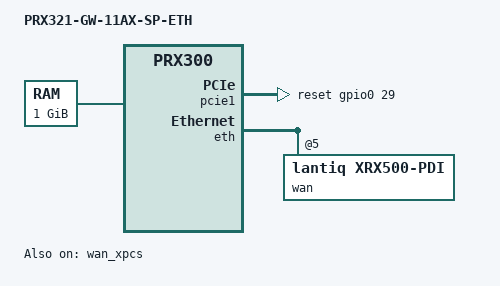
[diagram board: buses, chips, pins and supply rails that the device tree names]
/dts-v1/;
#include "prx321-gw-11ax-sp.dtsi"

/* Model configuration */
/ {
	model = "PRX321-GW-11AX-SP-ETH";
	compatible = "intel,prx321-gw-11ax-sp-eth", "intel,prx300";

	chosen {
		stdout-path = "serial0";
	};

	memory@0 {
		device_type = "memory";
		reg = <0x20000000 0x40000000>; /* 1024 MB */
	};
};

/* invert the reset polarity for VRX618 */
&pcie1 {
	reset-gpios = <&gpio0 29 GPIO_ACTIVE_HIGH>;
};

&eth {
	wan: interface@5 {
		compatible = "lantiq,xrx500-pdi";
		#address-cells = <1>;
		#size-cells = <0>;
		reg = <5>;
		lantiq,wan = <1>;
		intel,dp-dev-port = <2>;
		intel,dp-port-id = <2>;
		mac = <&gsw_mac0>;

		ethernet@5 {
			compatible = "lantiq,xrx500-pdi-port";
			reg = <1>;
			phy-mode = "rgmii";
		};
	};
};

&wan_xpcs {
	status = "okay";
	xpcs-mode = <0>;
};

/* use CPU3 for MPE firmware */
&cpu3 {
	default-OS = "MPEFW";
};

&gsw_core {
	intel,gsw-globalpce-rules = <256>;
};
